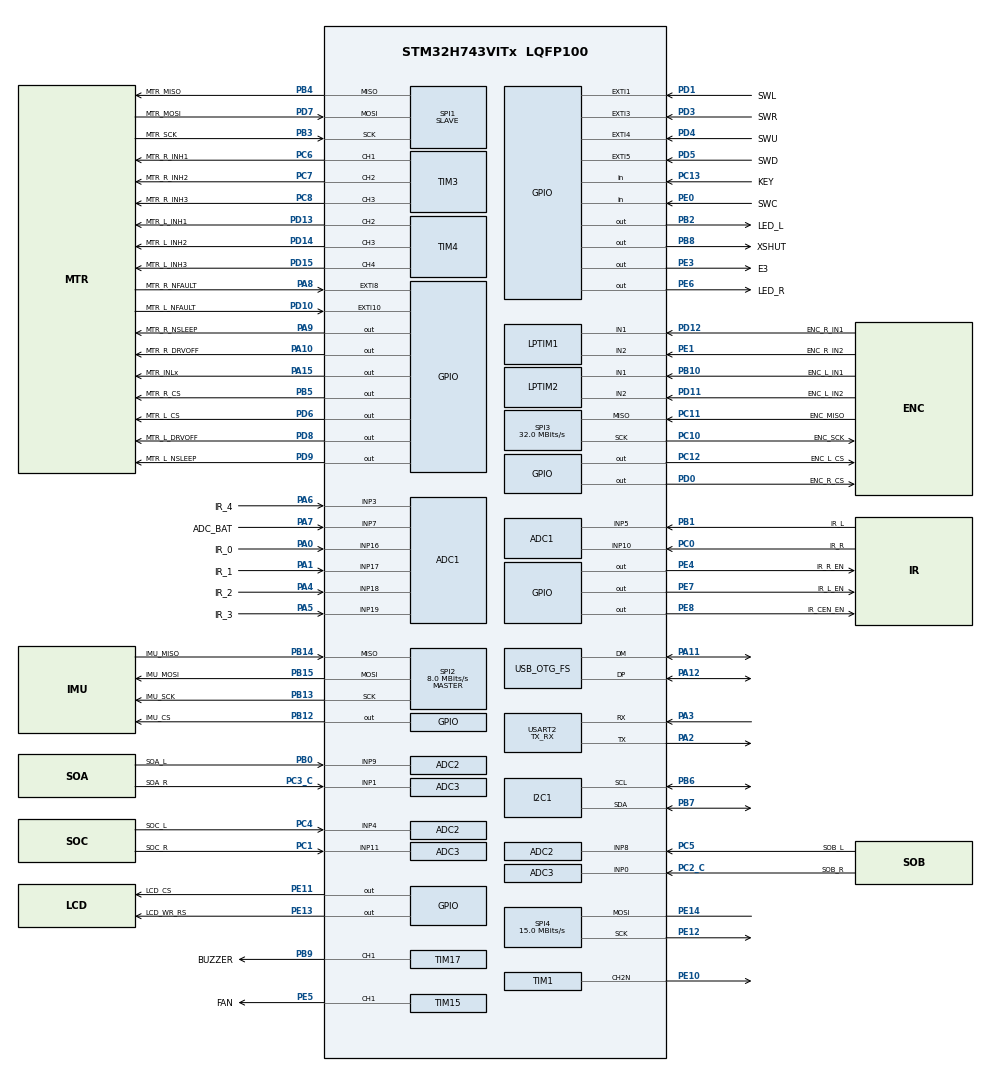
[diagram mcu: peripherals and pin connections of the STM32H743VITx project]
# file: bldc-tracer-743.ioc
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ADC1.Channel-3\#ChannelRegularConversion=ADC_CHANNEL_16
ADC1.NbrOfConversionFlag=1
ADC1.OffsetNumber-3\#ChannelRegularConversion=ADC_OFFSET_NONE
ADC1.OffsetSignedSaturation-3\#ChannelRegularConversion=DISABLE
ADC1.Rank-3\#ChannelRegularConversion=1
ADC1.SamplingTime-3\#ChannelRegularConversion=ADC_SAMPLETIME_1CYCLE_5
ADC1.master=1
ADC2.Channel-7\#ChannelRegularConversion=ADC_CHANNEL_9
ADC2.NbrOfConversionFlag=1
ADC2.OffsetNumber-7\#ChannelRegularConversion=ADC_OFFSET_NONE
ADC2.OffsetSignedSaturation-7\#ChannelRegularConversion=DISABLE
ADC2.Rank-7\#ChannelRegularConversion=1
ADC2.SamplingTime-7\#ChannelRegularConversion=ADC_SAMPLETIME_1CYCLE_5
ADC3.Channel-1\#ChannelRegularConversion=ADC_CHANNEL_11
ADC3.NbrOfConversionFlag=1
ADC3.OffsetNumber-1\#ChannelRegularConversion=ADC_OFFSET_NONE
ADC3.OffsetSignedSaturation-1\#ChannelRegularConversion=DISABLE
ADC3.Rank-1\#ChannelRegularConversion=1
ADC3.SamplingTime-1\#ChannelRegularConversion=ADC_SAMPLETIME_1CYCLE_5
I2C1.Timing=0x307075B1
LPTIM3.ClockPrescaler=LPTIM_PRESCALER_DIV1
LPTIM4.ClockPrescaler=LPTIM_PRESCALER_DIV16
LPTIM5.ClockPrescaler=LPTIM_PRESCALER_DIV16
Mcu.Family=STM32H7
Mcu.Name=STM32H743VITx
Mcu.Package=LQFP100
NVIC.LPTIM3_IRQn=true\:0\:0\:false\:false\:true\:true\:true\:true
NVIC.LPTIM4_IRQn=true\:0\:0\:false\:false\:true\:true\:true\:true
NVIC.LPTIM5_IRQn=true\:0\:0\:false\:false\:true\:true\:true\:true
NVIC.PriorityGroup=NVIC_PRIORITYGROUP_4
NVIC.TIM6_DAC_IRQn=true\:0\:0\:false\:false\:true\:true\:true\:true
PA0.GPIO_Label=IR_0
PA0.Mode=IN16-Single-Ended
PA0.Signal=ADC1_INP16
PA1.GPIO_Label=IR_1
PA1.Mode=IN17-Single-Ended
PA1.Signal=ADC1_INP17
PA10.GPIO_Label=MTR_R_DRVOFF
PA10.Signal=GPIO_Output
PA11.Mode=Host_Only
PA11.Signal=USB_OTG_FS_DM
PA12.Mode=Host_Only
PA12.Signal=USB_OTG_FS_DP
PA13\ (JTMS/SWDIO).Mode=Serial_Wire
PA13\ (JTMS/SWDIO).Signal=DEBUG_JTMS-SWDIO
PA14\ (JTCK/SWCLK).Mode=Serial_Wire
PA14\ (JTCK/SWCLK).Signal=DEBUG_JTCK-SWCLK
PA15\ (JTDI).GPIO_Label=MTR_INLx
PA15\ (JTDI).Signal=GPIO_Output
PA2.Mode=Asynchronous
PA2.Signal=USART2_TX
PA3.Mode=Asynchronous
PA3.Signal=USART2_RX
PA4.GPIO_Label=IR_2
PA4.Signal=ADCx_INP18
PA5.GPIO_Label=IR_3
PA5.Signal=ADCx_INP19
PA6.GPIO_Label=IR_4
PA6.Signal=ADCx_INP3
PA7.GPIO_Label=ADC_BAT
PA7.Signal=ADCx_INP7
PA8.GPIO_Label=MTR_R_NFAULT
PA8.Signal=GPXTI8
PA9.GPIO_Label=MTR_R_NSLEEP
PA9.Signal=GPIO_Output
PB0.GPIO_Label=SOA_L
PB0.Signal=ADCx_INP9
PB1.GPIO_Label=IR_L
PB1.Signal=ADCx_INP5
PB10.GPIO_Label=ENC_L_IN1
PB10.Mode=Encoder_mode_occur1
PB10.Signal=LPTIM2_IN1
PB12.GPIO_Label=IMU_CS
PB12.Signal=GPIO_Output
PB13.GPIO_Label=IMU_SCK
PB13.Mode=Full_Duplex_Master
PB13.Signal=SPI2_SCK
PB14.GPIO_Label=IMU_MISO
PB14.Mode=Full_Duplex_Master
PB14.Signal=SPI2_MISO
PB15.GPIO_Label=IMU_MOSI
PB15.Mode=Full_Duplex_Master
PB15.Signal=SPI2_MOSI
PB2.GPIO_Label=LED_L
PB2.Signal=GPIO_Output
PB3\ (JTDO/TRACESWO).GPIO_Label=MTR_SCK
PB3\ (JTDO/TRACESWO).Mode=Full_Duplex_Slave
PB3\ (JTDO/TRACESWO).Signal=SPI1_SCK
PB4\ (NJTRST).GPIO_Label=MTR_MISO
PB4\ (NJTRST).Mode=Full_Duplex_Slave
PB4\ (NJTRST).Signal=SPI1_MISO
PB5.GPIO_Label=MTR_R_CS
PB5.Signal=GPIO_Output
PB6.Mode=I2C
PB6.Signal=I2C1_SCL
PB7.Mode=I2C
PB7.Signal=I2C1_SDA
PB8.GPIO_Label=XSHUT
PB8.Signal=GPIO_Output
PB9.GPIO_Label=BUZZER
PB9.Signal=S_TIM17_CH1
PC0.GPIO_Label=IR_R
PC0.Signal=ADCx_INP10
PC1.GPIO_Label=SOC_R
PC1.Signal=ADCx_INP11
PC10.GPIO_Label=ENC_SCK
PC10.Mode=RX_Only_Simplex_Unidirect_Master
PC10.Signal=SPI3_SCK
PC11.GPIO_Label=ENC_MISO
PC11.Mode=RX_Only_Simplex_Unidirect_Master
PC11.Signal=SPI3_MISO
PC12.GPIO_Label=ENC_L_CS
PC12.Signal=GPIO_Output
PC13.GPIO_Label=KEY
PC13.GPIO_PuPd=GPIO_PULLDOWN
PC13.Signal=GPIO_Input
PC14-OSC32_IN\ (OSC32_IN).Mode=LSE-External-Oscillator
PC14-OSC32_IN\ (OSC32_IN).Signal=RCC_OSC32_IN
PC15-OSC32_OUT\ (OSC32_OUT).Mode=LSE-External-Oscillator
PC15-OSC32_OUT\ (OSC32_OUT).Signal=RCC_OSC32_OUT
PC2_C.GPIO_Label=SOB_R
PC2_C.Mode=IN0-Single-Ended
PC2_C.Signal=ADC3_INP0
PC3_C.GPIO_Label=SOA_R
PC3_C.Mode=IN1-Single-Ended
PC3_C.Signal=ADC3_INP1
PC4.GPIO_Label=SOC_L
PC4.Signal=ADCx_INP4
PC5.GPIO_Label=SOB_L
PC5.Signal=ADCx_INP8
PC6.GPIO_Label=MTR_R_INH1
PC6.Signal=S_TIM3_CH1
PC7.GPIO_Label=MTR_R_INH2
PC7.Signal=S_TIM3_CH2
PC8.GPIO_Label=MTR_R_INH3
PC8.Signal=S_TIM3_CH3
PD0.GPIO_Label=ENC_R_CS
PD0.Signal=GPIO_Output
PD1.GPIO_Label=SWL
PD1.Signal=GPXTI1
PD10.GPIO_Label=MTR_L_NFAULT
PD10.Signal=GPXTI10
PD11.GPIO_Label=ENC_L_IN2
PD11.Mode=Encoder_mode_occur1
PD11.Signal=LPTIM2_IN2
PD12.GPIO_Label=ENC_R_IN1
PD12.Mode=Encoder_mode_occur1
PD12.Signal=LPTIM1_IN1
PD13.GPIO_Label=MTR_L_INH1
PD13.Signal=S_TIM4_CH2
PD14.GPIO_Label=MTR_L_INH2
PD14.Signal=S_TIM4_CH3
PD15.GPIO_Label=MTR_L_INH3
PD15.Signal=S_TIM4_CH4
PD3.GPIO_Label=SWR
PD3.Signal=GPXTI3
PD4.GPIO_Label=SWU
PD4.Signal=GPXTI4
PD5.GPIO_Label=SWD
PD5.Signal=GPXTI5
PD6.GPIO_Label=MTR_L_CS
PD6.Signal=GPIO_Output
PD7.GPIO_Label=MTR_MOSI
PD7.Mode=Full_Duplex_Slave
PD7.Signal=SPI1_MOSI
PD8.GPIO_Label=MTR_L_DRVOFF
PD8.Signal=GPIO_Output
PD9.GPIO_Label=MTR_L_NSLEEP
PD9.Signal=GPIO_Output
PE0.GPIO_Label=SWC
PE0.Signal=GPIO_Input
PE1.GPIO_Label=ENC_R_IN2
PE1.Mode=Encoder_mode_occur1
PE1.Signal=LPTIM1_IN2
PE10.Mode=PWM Generation2 CH2N
PE10.Signal=TIM1_CH2N
PE11.GPIO_Label=LCD_CS
PE11.GPIO_Speed=GPIO_SPEED_FREQ_VERY_HIGH
PE11.PinState=GPIO_PIN_SET
PE11.Signal=GPIO_Output
PE12.GPIO_Speed=GPIO_SPEED_FREQ_HIGH
PE12.Mode=Simplex_Bidirectional_Master
PE12.Signal=SPI4_SCK
PE13.GPIO_Label=LCD_WR_RS
PE13.GPIO_Speed=GPIO_SPEED_FREQ_VERY_HIGH
PE13.PinState=GPIO_PIN_SET
PE13.Signal=GPIO_Output
PE14.GPIO_Speed=GPIO_SPEED_FREQ_HIGH
PE14.Mode=Simplex_Bidirectional_Master
PE14.Signal=SPI4_MOSI
PE3.GPIO_Label=E3
PE3.Signal=GPIO_Output
PE4.GPIO_Label=IR_R_EN
PE4.Signal=GPIO_Output
PE5.GPIO_Label=FAN
PE5.Signal=S_TIM15_CH1
PE6.GPIO_Label=LED_R
PE6.Signal=GPIO_Output
PE7.GPIO_Label=IR_L_EN
PE7.Signal=GPIO_Output
PE8.GPIO_Label=IR_CEN_EN
PE8.Signal=GPIO_Output
PH0-OSC_IN\ (PH0).Mode=HSE-External-Oscillator
PH0-OSC_IN\ (PH0).Signal=RCC_OSC_IN
PH1-OSC_OUT\ (PH1).Mode=HSE-External-Oscillator
PH1-OSC_OUT\ (PH1).Signal=RCC_OSC_OUT
ProjectManager.HeapSize=0x200
ProjectManager.StackSize=0x400
ProjectManager.TargetToolchain=STM32CubeIDE
RCC.ADCFreq_Value=75000000
RCC.APB1Freq_Value=120000000
RCC.APB2Freq_Value=120000000
RCC.APB3Freq_Value=120000000
RCC.APB4Freq_Value=120000000
RCC.CortexFreq_Value=480000000
RCC.D1PPRE=RCC_APB3_DIV2
RCC.D2PPRE1=RCC_APB1_DIV2
RCC.D2PPRE2=RCC_APB2_DIV2
RCC.D3PPRE=RCC_APB4_DIV2
RCC.DIVM1=5
RCC.DIVM2=2
RCC.DIVN1=192
RCC.DIVN2=12
RCC.DIVQ1=5
RCC.DIVQ2=1
RCC.HCLKFreq_Value=240000000
RCC.HPRE=RCC_HCLK_DIV2
RCC.HSE_VALUE=25000000
RCC.LPTIM345CLockSelection=RCC_LPTIM345CLKSOURCE_LSI
RCC.PLL2FRACN=0
RCC.PLLFRACN=0
RCC.PLLSourceVirtual=RCC_PLLSOURCE_HSE
RCC.PWR_Regulator_Voltage_Scale=PWR_REGULATOR_VOLTAGE_SCALE0
RCC.RTCClockSelection=RCC_RTCCLKSOURCE_LSE
RCC.SDMMC1CLockSelection=RCC_SDMMCCLKSOURCE_PLL2
RCC.SPI123CLockSelection=RCC_SPI123CLKSOURCE_CLKP
RCC.SYSCLKFreq_VALUE=480000000
RCC.SYSCLKSource=RCC_SYSCLKSOURCE_PLLCLK
RCC.USBCLockSelection=RCC_USBCLKSOURCE_HSI48
RCC.USBFreq_Value=48000000
RTC.Hours=12
RTC.Month=RTC_MONTH_JUNE
RTC.Year=20
SH.ADCx_INP10.0=ADC1_INP10,IN10-Single-Ended
SH.ADCx_INP11.0=ADC3_INP11,IN11-Single-Ended
SH.ADCx_INP18.0=ADC1_INP18,IN18-Single-Ended
SH.ADCx_INP19.0=ADC1_INP19,IN19-Single-Ended
SH.ADCx_INP3.0=ADC1_INP3,IN3-Single-Ended
SH.ADCx_INP4.0=ADC2_INP4,IN4-Single-Ended
SH.ADCx_INP5.0=ADC1_INP5,IN5-Single-Ended
SH.ADCx_INP7.0=ADC1_INP7,IN7-Single-Ended
SH.ADCx_INP8.0=ADC2_INP8,IN8-Single-Ended
SH.ADCx_INP9.0=ADC2_INP9,IN9-Single-Ended
SH.S_TIM15_CH1.0=TIM15_CH1,PWM Generation1 CH1
SH.S_TIM17_CH1.0=TIM17_CH1,PWM Generation1 CH1
SH.S_TIM3_CH1.0=TIM3_CH1,PWM Generation1 CH1
SH.S_TIM3_CH2.0=TIM3_CH2,PWM Generation2 CH2
SH.S_TIM3_CH3.0=TIM3_CH3,PWM Generation3 CH3
SH.S_TIM4_CH2.0=TIM4_CH2,PWM Generation2 CH2
SH.S_TIM4_CH3.0=TIM4_CH3,PWM Generation3 CH3
SH.S_TIM4_CH4.0=TIM4_CH4,PWM Generation4 CH4
SPI1.DataSize=SPI_DATASIZE_8BIT
SPI1.Direction=SPI_DIRECTION_2LINES
SPI1.Mode=SPI_MODE_SLAVE
SPI1.VirtualType=VM_SLAVE
SPI2.BaudRatePrescaler=SPI_BAUDRATEPRESCALER_8
SPI2.CalculateBaudRate=8.0 MBits/s
SPI2.DataSize=SPI_DATASIZE_8BIT
SPI2.Direction=SPI_DIRECTION_2LINES
SPI2.Mode=SPI_MODE_MASTER
SPI2.VirtualType=VM_MASTER
SPI3.CalculateBaudRate=32.0 MBits/s
SPI3.Direction=SPI_DIRECTION_2LINES_RXONLY
SPI3.Mode=SPI_MODE_MASTER
SPI3.VirtualType=VM_MASTER
SPI4.BaudRatePrescaler=SPI_BAUDRATEPRESCALER_8
SPI4.CalculateBaudRate=15.0 MBits/s
SPI4.DataSize=SPI_DATASIZE_8BIT
SPI4.Direction=SPI_DIRECTION_1LINE
SPI4.Mode=SPI_MODE_MASTER
SPI4.VirtualType=VM_MASTER
TIM1.AutoReloadPreload=TIM_AUTORELOAD_PRELOAD_ENABLE
TIM1.AutomaticOutput=TIM_AUTOMATICOUTPUT_ENABLE
TIM1.Channel-PWM\ Generation2\ CH2N=TIM_CHANNEL_2
TIM1.OCMode_PWM-PWM\ Generation2\ CH2N=TIM_OCMODE_PWM2
TIM1.Period=999
TIM1.Prescaler=11
TIM15.Channel-PWM\ Generation1\ CH1=TIM_CHANNEL_1
TIM15.Period=319
TIM15.Prescaler=239
TIM16.Prescaler=599
TIM17.Channel=TIM_CHANNEL_1
TIM17.Period=999
TIM17.Prescaler=11
TIM3.Channel-PWM\ Generation1\ CH1=TIM_CHANNEL_1
TIM3.Channel-PWM\ Generation2\ CH2=TIM_CHANNEL_2
TIM3.Channel-PWM\ Generation3\ CH3=TIM_CHANNEL_3
TIM4.Channel-PWM\ Generation2\ CH2=TIM_CHANNEL_2
TIM4.Channel-PWM\ Generation3\ CH3=TIM_CHANNEL_3
TIM4.Channel-PWM\ Generation4\ CH4=TIM_CHANNEL_4
USART2.Mode=MODE_TX_RX
USART2.VirtualMode-Asynchronous=VM_ASYNC
USB_OTG_FS.VirtualMode=Host_Only
USB_OTG_FS.phy_itface=HCD_PHY_EMBEDDED
VP_LPTIM3_VS_LPTIM_counterModeInternalClock.Mode=Counts__internal_clock_event_00
VP_LPTIM4_VS_LPTIM_counterModeInternalClock.Mode=Counts__internal_clock_event_00
VP_LPTIM5_VS_LPTIM_counterModeInternalClock.Mode=Counts__internal_clock_event_00
VP_MEMORYMAP_VS_MEMORYMAP.Mode=CurAppReg
VP_RTC_VS_RTC_Activate.Mode=RTC_Enabled
VP_RTC_VS_RTC_Calendar.Mode=RTC_Calendar
VP_TIM15_VS_ClockSourceINT.Mode=Internal
VP_TIM16_VS_ClockSourceINT.Mode=Enable_Timer
VP_TIM17_VS_ClockSourceINT.Mode=Enable_Timer
VP_TIM1_VS_ClockSourceINT.Mode=Internal
VP_TIM6_VS_ClockSourceINT.Mode=Enable_Timer
VP_TIM7_VS_ClockSourceINT.Mode=Enable_Timer
board=custom

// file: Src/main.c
/* USER CODE BEGIN Header */
/**
 ******************************************************************************
 * @file           : main.c
 * @brief          : Main program body
 ******************************************************************************
 * @attention
 *
 * <h2><center>&copy; Copyright (c) 2020 STMicroelectronics.
 * All rights reserved.</center></h2>
 *
 * This software component is licensed by ST under BSD 3-Clause license,
 * the "License"; You may not use this file except in compliance with the
 * License. You may obtain a copy of the License at:
 *                        opensource.org/licenses/BSD-3-Clause
 *
 ******************************************************************************
 */
/* USER CODE END Header */
#include "main.h"
#include "adc.h"
#include "i2c.h"
#include "lptim.h"
#include "rtc.h"
#include "spi.h"
#include "tim.h"
#include "usart.h"
#include "usb_otg.h"
#include "gpio.h"

/* USER CODE BEGIN Includes */
#include "dwt_delay.h"
#include "st7789.h"
#include "init.h"
#include "vl53l0x_api.h"
#include "vl53l0x_platform.h"
#include <stdio.h>

/* USER CODE END Includes */

/* USER CODE BEGIN PV */
VL53L0X_Dev_t dev; // 센서 디바이스 핸들
VL53L0X_RangingMeasurementData_t measureData; // 측정 결과 저장 구조체
/* USER CODE END PV */

void SystemClock_Config(void);
void PeriphCommonClock_Config(void);

/* USER CODE BEGIN 0 */
static void MPU_Config(void) {
	MPU_Region_InitTypeDef MPU_InitStruct = { 0 };

	/* Disables the MPU */
	HAL_MPU_Disable();

	/* Configure the MPU attributes for the QSPI 256MB without instruction access */
	MPU_InitStruct.Enable = MPU_REGION_ENABLE;
	MPU_InitStruct.Number = MPU_REGION_NUMBER0;
	MPU_InitStruct.BaseAddress = QSPI_BASE;
	MPU_InitStruct.Size = MPU_REGION_SIZE_256MB;
	MPU_InitStruct.AccessPermission = MPU_REGION_NO_ACCESS;
	MPU_InitStruct.IsBufferable = MPU_ACCESS_NOT_BUFFERABLE;
	MPU_InitStruct.IsCacheable = MPU_ACCESS_NOT_CACHEABLE;
	MPU_InitStruct.IsShareable = MPU_ACCESS_NOT_SHAREABLE;
	MPU_InitStruct.DisableExec = MPU_INSTRUCTION_ACCESS_DISABLE;
	MPU_InitStruct.TypeExtField = MPU_TEX_LEVEL1;
	MPU_InitStruct.SubRegionDisable = 0x00;
	HAL_MPU_ConfigRegion(&MPU_InitStruct);

	/* Configure the MPU attributes for the QSPI 8MB (QSPI Flash Size) to Cacheable WT */
	MPU_InitStruct.Enable = MPU_REGION_ENABLE;
	MPU_InitStruct.Number = MPU_REGION_NUMBER1;
	MPU_InitStruct.BaseAddress = QSPI_BASE;
	MPU_InitStruct.Size = MPU_REGION_SIZE_8MB;
	MPU_InitStruct.AccessPermission = MPU_REGION_PRIV_RO;
	MPU_InitStruct.IsBufferable = MPU_ACCESS_BUFFERABLE;
	MPU_InitStruct.IsCacheable = MPU_ACCESS_CACHEABLE;
	MPU_InitStruct.IsShareable = MPU_ACCESS_NOT_SHAREABLE;
	MPU_InitStruct.DisableExec = MPU_INSTRUCTION_ACCESS_ENABLE;
	MPU_InitStruct.TypeExtField = MPU_TEX_LEVEL1;
	MPU_InitStruct.SubRegionDisable = 0x00;
	HAL_MPU_ConfigRegion(&MPU_InitStruct);

	/* Enables the MPU */
	HAL_MPU_Enable(MPU_PRIVILEGED_DEFAULT);
}

static void CPU_CACHE_Enable(void) {
	/* Enable I-Cache */
	SCB_EnableICache();

	/* Enable D-Cache */
	SCB_EnableDCache();
}

static void LED_Blink(uint32_t Hdelay, uint32_t Ldelay) {
	HAL_GPIO_WritePin(E3_GPIO_Port, E3_Pin, GPIO_PIN_SET);
	HAL_Delay(Hdelay - 1);
	HAL_GPIO_WritePin(E3_GPIO_Port, E3_Pin, GPIO_PIN_RESET);
	HAL_Delay(Ldelay - 1);
}

void VL53L0X_Setup(void) {
	uint32_t refSpadCount;
	uint8_t isApertureSpads;
	uint8_t VhvSettings;
	uint8_t PhaseCal;

	// 1. 디바이스 주소 및 통신 설정
	dev.I2cDevAddr = 0x29 << 1; // 기본 I2C 주소 (0x52)
	dev.comms_type = 1;         // I2C 통신
	dev.comms_speed_khz = 400;  // 400kHz

	// 2. 초기화 (순서 중요)
	// DataInit -> StaticInit -> SPAD/Ref 보정 -> 모드 설정 -> 측정 시작
	if (VL53L0X_DataInit(&dev) != VL53L0X_ERROR_NONE) {
		ST7789_DrawUser8x16(0, 48, "DataInit Fail", ST7789_RED, ST7789_BLACK);
		return;
	}

	VL53L0X_StaticInit(&dev);

	// 3. 레퍼런스 SPAD 및 온도/전압 보정
	VL53L0X_PerformRefSpadManagement(&dev, &refSpadCount, &isApertureSpads);
	VL53L0X_PerformRefCalibration(&dev, &VhvSettings, &PhaseCal);

	// 4. 연속 측정 모드 설정 (Continuous Ranging)
	VL53L0X_SetDeviceMode(&dev, VL53L0X_DEVICEMODE_CONTINUOUS_RANGING);

	// 5. 측정 시작
	VL53L0X_StartMeasurement(&dev);
}

/* USER CODE END 0 */

int main(void)
{

  /* USER CODE BEGIN 1 */

#ifdef W25Qxx
    SCB->VTOR = QSPI_BASE;
  #endif
	MPU_Config();
	CPU_CACHE_Enable();

  /* USER CODE END 1 */

  /* MCU Configuration--------------------------------------------------------*/

  /* Reset of all peripherals, Initializes the Flash interface and the Systick. */
  HAL_Init();

  /* Configure the system clock */
  SystemClock_Config();

  /* Configure the peripherals common clocks */
  PeriphCommonClock_Config();

  /* Initialize all configured peripherals */
  MX_GPIO_Init();
  MX_RTC_Init();
  MX_SPI4_Init();
  MX_TIM1_Init();
  MX_ADC1_Init();
  MX_LPTIM1_Init();
  MX_LPTIM2_Init();
  MX_SPI1_Init();
  MX_SPI2_Init();
  MX_TIM6_Init();
  MX_TIM16_Init();
  MX_TIM17_Init();
  MX_LPTIM3_Init();
  MX_LPTIM4_Init();
  MX_TIM7_Init();
  MX_LPTIM5_Init();
  MX_ADC3_Init();
  MX_TIM15_Init();
  MX_ADC2_Init();
  MX_TIM3_Init();
  MX_TIM4_Init();
  MX_USB_OTG_FS_HCD_Init();
  MX_USART2_UART_Init();
  MX_SPI3_Init();
  MX_I2C1_Init();
  /* USER CODE BEGIN 2 */
	DWT_Delay_Init();
	ST7789_Init();

	HAL_TIMEx_PWMN_Start(&htim1, TIM_CHANNEL_2);
	__HAL_TIM_SetCompare(&htim1,TIM_CHANNEL_2,300);

	ST7789_DrawUser8x16(0, 0, "Hello World", ST7789_WHITE, ST7789_BLACK);
	HAL_GPIO_WritePin(XSHUT_GPIO_Port, XSHUT_Pin, GPIO_PIN_RESET); // 1. 센서 끄기 (Reset)
	HAL_Delay(100);                                             // 2. 잠시 대기 (방전)
	HAL_GPIO_WritePin(XSHUT_GPIO_Port, XSHUT_Pin, GPIO_PIN_SET); // 3. 센서 켜기 (Boot)
	HAL_Delay(100);                                             // 4. 부팅 대기 (필수)

	HAL_Delay(2000); // 결과 확인할 시간 벌기

	VL53L0X_Setup();

	HAL_GPIO_WritePin(E3_GPIO_Port, E3_Pin, GPIO_PIN_RESET);
	ST7789_DrawUser8x16(0, 16, "TOF Running...", ST7789_GREEN, ST7789_BLACK);
  /* USER CODE END 2 */

  /* Infinite loop */
  /* USER CODE BEGIN WHILE */
	char distStr[20];

	while (1) {
    /* USER CODE END WHILE */

    /* USER CODE BEGIN 3 */
		// 1. 데이터 읽기 (이 함수 내부에서 데이터 준비될 때까지 기다리거나 polling 함)
		VL53L0X_GetRangingMeasurementData(&dev, &measureData);

		// 2. 상태 확인 및 출력 (RangeStatus 0이면 정상)
		if (measureData.RangeStatus == 0) {
			// 거리값은 measureData.RangeMilliMeter에 들어있음 (단위: mm)
			sprintf(distStr, "Dist: %4d mm", measureData.RangeMilliMeter);

			// LCD에 표시 (좌표 0, 32)
			ST7789_DrawUser8x16(0, 32, distStr, ST7789_CYAN, ST7789_BLACK);
		} else {
			// 에러 상황 (범위 벗어남 등)
			sprintf(distStr, "Err: %d      ", measureData.RangeStatus);
			ST7789_DrawUser8x16(0, 32, distStr, ST7789_RED, ST7789_BLACK);
		}

		// 3. 인터럽트 플래그 클리어 (연속 모드에서 필수!)
		VL53L0X_ClearInterruptMask(&dev, 0);
	}
  /* USER CODE END 3 */
}

void SystemClock_Config(void)
{
  RCC_OscInitTypeDef RCC_OscInitStruct = {0};
  RCC_ClkInitTypeDef RCC_ClkInitStruct = {0};

  /** Supply configuration update enable
  */
  HAL_PWREx_ConfigSupply(PWR_LDO_SUPPLY);

  /** Configure the main internal regulator output voltage
  */
  __HAL_PWR_VOLTAGESCALING_CONFIG(PWR_REGULATOR_VOLTAGE_SCALE0);

  while(!__HAL_PWR_GET_FLAG(PWR_FLAG_VOSRDY)) {}

  /** Configure LSE Drive Capability
  */
  HAL_PWR_EnableBkUpAccess();
  __HAL_RCC_LSEDRIVE_CONFIG(RCC_LSEDRIVE_LOW);

  /** Initializes the RCC Oscillators according to the specified parameters
  * in the RCC_OscInitTypeDef structure.
  */
  RCC_OscInitStruct.OscillatorType = RCC_OSCILLATORTYPE_HSI48|RCC_OSCILLATORTYPE_HSI
                              |RCC_OSCILLATORTYPE_LSI|RCC_OSCILLATORTYPE_HSE
                              |RCC_OSCILLATORTYPE_LSE;
  RCC_OscInitStruct.HSEState = RCC_HSE_ON;
  RCC_OscInitStruct.LSEState = RCC_LSE_ON;
  RCC_OscInitStruct.HSIState = RCC_HSI_DIV1;
  RCC_OscInitStruct.HSICalibrationValue = RCC_HSICALIBRATION_DEFAULT;
  RCC_OscInitStruct.LSIState = RCC_LSI_ON;
  RCC_OscInitStruct.HSI48State = RCC_HSI48_ON;
  RCC_OscInitStruct.PLL.PLLState = RCC_PLL_ON;
  RCC_OscInitStruct.PLL.PLLSource = RCC_PLLSOURCE_HSE;
  RCC_OscInitStruct.PLL.PLLM = 5;
  RCC_OscInitStruct.PLL.PLLN = 192;
  RCC_OscInitStruct.PLL.PLLP = 2;
  RCC_OscInitStruct.PLL.PLLQ = 5;
  RCC_OscInitStruct.PLL.PLLR = 2;
  RCC_OscInitStruct.PLL.PLLRGE = RCC_PLL1VCIRANGE_2;
  RCC_OscInitStruct.PLL.PLLVCOSEL = RCC_PLL1VCOWIDE;
  RCC_OscInitStruct.PLL.PLLFRACN = 0;
  if (HAL_RCC_OscConfig(&RCC_OscInitStruct) != HAL_OK)
  {
    Error_Handler();
  }

  /** Initializes the CPU, AHB and APB buses clocks
  */
  RCC_ClkInitStruct.ClockType = RCC_CLOCKTYPE_HCLK|RCC_CLOCKTYPE_SYSCLK
                              |RCC_CLOCKTYPE_PCLK1|RCC_CLOCKTYPE_PCLK2
                              |RCC_CLOCKTYPE_D3PCLK1|RCC_CLOCKTYPE_D1PCLK1;
  RCC_ClkInitStruct.SYSCLKSource = RCC_SYSCLKSOURCE_PLLCLK;
  RCC_ClkInitStruct.SYSCLKDivider = RCC_SYSCLK_DIV1;
  RCC_ClkInitStruct.AHBCLKDivider = RCC_HCLK_DIV2;
  RCC_ClkInitStruct.APB3CLKDivider = RCC_APB3_DIV2;
  RCC_ClkInitStruct.APB1CLKDivider = RCC_APB1_DIV2;
  RCC_ClkInitStruct.APB2CLKDivider = RCC_APB2_DIV2;
  RCC_ClkInitStruct.APB4CLKDivider = RCC_APB4_DIV2;

  if (HAL_RCC_ClockConfig(&RCC_ClkInitStruct, FLASH_LATENCY_4) != HAL_OK)
  {
    Error_Handler();
  }
}

void PeriphCommonClock_Config(void)
{
  RCC_PeriphCLKInitTypeDef PeriphClkInitStruct = {0};

  /** Initializes the peripherals clock
  */
  PeriphClkInitStruct.PeriphClockSelection = RCC_PERIPHCLK_ADC|RCC_PERIPHCLK_CKPER;
  PeriphClkInitStruct.PLL2.PLL2M = 2;
  PeriphClkInitStruct.PLL2.PLL2N = 12;
  PeriphClkInitStruct.PLL2.PLL2P = 2;
  PeriphClkInitStruct.PLL2.PLL2Q = 1;
  PeriphClkInitStruct.PLL2.PLL2R = 2;
  PeriphClkInitStruct.PLL2.PLL2RGE = RCC_PLL2VCIRANGE_3;
  PeriphClkInitStruct.PLL2.PLL2VCOSEL = RCC_PLL2VCOMEDIUM;
  PeriphClkInitStruct.PLL2.PLL2FRACN = 0;
  PeriphClkInitStruct.CkperClockSelection = RCC_CLKPSOURCE_HSI;
  PeriphClkInitStruct.AdcClockSelection = RCC_ADCCLKSOURCE_PLL2;
  if (HAL_RCCEx_PeriphCLKConfig(&PeriphClkInitStruct) != HAL_OK)
  {
    Error_Handler();
  }
}

void Error_Handler(void)
{
  /* USER CODE BEGIN Error_Handler_Debug */
	/* User can add his own implementation to report the HAL error return state */
	while (1) {
		LED_Blink(500, 500);
	}
  /* USER CODE END Error_Handler_Debug */
}
